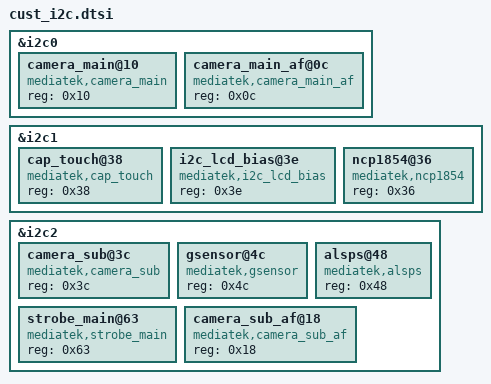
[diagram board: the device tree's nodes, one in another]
/*
 * Generated by MTK SP Drv_CodeGen Version 03.13.6  for MT6735. Copyright MediaTek Inc. (C) 2013.
 * Thu Jun  4 21:49:55 2015
 * Do Not Modify the File.
 */

/*************************
 * I2C dtsi file
*************************/

&i2c0 {
	camera_main@10 {
		compatible = "mediatek,camera_main";
		reg = <0x10>;
	};

	camera_main_af@0c {
		compatible = "mediatek,camera_main_af";
		reg = <0x0c>;
	};

};

&i2c1 {
	cap_touch@38 {
		compatible = "mediatek,cap_touch";
		reg = <0x38>;
			};

	i2c_lcd_bias@3e {
		compatible = "mediatek,i2c_lcd_bias";
		reg = <0x3e>;
			};

	ncp1854@36 {
		compatible = "mediatek,ncp1854";
		reg = <0x36>;
			};
		};

&i2c2 {

	camera_sub@3c {
		compatible = "mediatek,camera_sub";
		reg = <0x3c>;
			};

	gsensor@4c {
		compatible = "mediatek,gsensor";
		reg = <0x4c>;
			};

	alsps@48 {
		compatible = "mediatek,alsps";
		reg = <0x48>;
			};

	strobe_main@63 {
		compatible = "mediatek,strobe_main";
		reg = <0x63>;
			};

	camera_sub_af@18 {
		compatible = "mediatek,camera_sub_af";
		reg = <0x18>;
			};
		};
